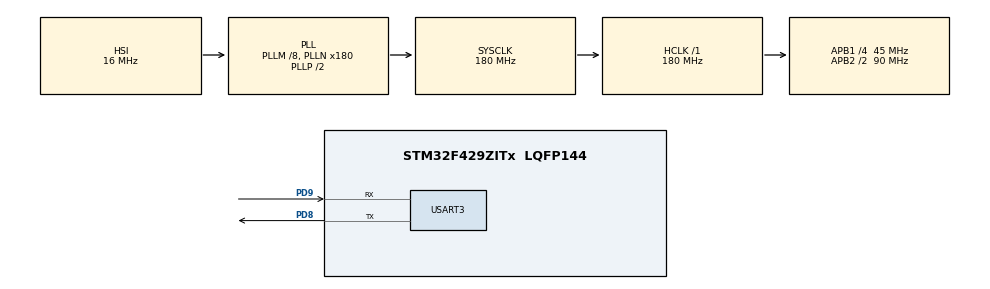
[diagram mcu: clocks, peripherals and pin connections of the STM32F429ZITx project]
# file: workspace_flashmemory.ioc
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Mcu.Family=STM32F4
Mcu.Name=STM32F429ZITx
Mcu.Package=LQFP144
NVIC.PriorityGroup=NVIC_PRIORITYGROUP_4
PA13.Mode=Serial_Wire
PA13.Signal=SYS_JTMS-SWDIO
PA14.Mode=Serial_Wire
PA14.Signal=SYS_JTCK-SWCLK
PC14/OSC32_IN.Mode=LSE-External-Oscillator
PC14/OSC32_IN.Signal=RCC_OSC32_IN
PC15/OSC32_OUT.Mode=LSE-External-Oscillator
PC15/OSC32_OUT.Signal=RCC_OSC32_OUT
PD8.Mode=Asynchronous
PD8.Signal=USART3_TX
PD9.Mode=Asynchronous
PD9.Signal=USART3_RX
ProjectManager.HeapSize=0x200
ProjectManager.StackSize=0x400
ProjectManager.TargetToolchain=STM32CubeIDE
RCC.48MHZClocksFreq_Value=90000000
RCC.AHBFreq_Value=180000000
RCC.APB1CLKDivider=RCC_HCLK_DIV4
RCC.APB1Freq_Value=45000000
RCC.APB1TimFreq_Value=90000000
RCC.APB2CLKDivider=RCC_HCLK_DIV2
RCC.APB2Freq_Value=90000000
RCC.APB2TimFreq_Value=180000000
RCC.CortexFreq_Value=180000000
RCC.HCLKFreq_Value=180000000
RCC.HSE_VALUE=25000000
RCC.HSI_VALUE=16000000
RCC.PLLM=8
RCC.PLLN=180
RCC.RCC_RTC_Clock_Source=RCC_RTCCLKSOURCE_LSE
RCC.SYSCLKFreq_VALUE=180000000
RCC.SYSCLKSource=RCC_SYSCLKSOURCE_PLLCLK
RCC.VCOOutputFreq_Value=360000000
USART3.VirtualMode=VM_ASYNC
VP_RTC_VS_RTC_Activate.Mode=RTC_Enabled
board=custom

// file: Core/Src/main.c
/* USER CODE BEGIN Header */
/**
  ******************************************************************************
  * @file           : main.c
  * @brief          : Main program body
  ******************************************************************************
  * @attention
  *
  * Copyright (c) 2022 STMicroelectronics.
  * All rights reserved.
  *
  * This software is licensed under terms that can be found in the LICENSE file
  * in the root directory of this software component.
  * If no LICENSE file comes with this software, it is provided AS-IS.
  *
  ******************************************************************************
  */
/* USER CODE END Header */
#include "main.h"
#include "rtc.h"
#include "usart.h"
#include "gpio.h"

/* USER CODE BEGIN PTD */
typedef struct FLAHTIME{
	uint8_t year;
	uint8_t month;
	uint8_t day;
	uint8_t format;
	uint8_t hour;
	uint8_t minutes;
	uint8_t seconds;
	uint8_t alramFormat;
	uint8_t alramHour;
	uint8_t alramMinutes;
	uint8_t alramSeconds;

} FT;
/* USER CODE END PTD */

/* USER CODE BEGIN PD */
#define FLASH_USER_START_ADDR   ADDR_FLASH_SECTOR_12   /* Start @ of user Flash area */
#define FLASH_USER_END_ADDR     ADDR_FLASH_SECTOR_23  +  GetSectorSize(ADDR_FLASH_SECTOR_23) - 1 /* End @ of user Flash area : sector start address + sector size -1 */

#define DATA_32                 ((uint32_t)0x12300078)

/* USER CODE END PD */

void SystemClock_Config(void);

/* USER CODE BEGIN 0 */
static FLASH_EraseInitTypeDef EraseInitStruct;
static uint32_t GetSector(uint32_t Address);
uint32_t FirstSector = 0, NbOfSectors = 0;
uint32_t Address = 0, SECTORError = 0;
__IO uint32_t data32 = 0 , MemoryProgramStatus = 0;
static uint32_t GetSectorSize(uint32_t Sector);
FT flashTime;
/* USER CODE END 0 */

int main(void)
{

  /* MCU Configuration--------------------------------------------------------*/

  /* Reset of all peripherals, Initializes the Flash interface and the Systick. */
  HAL_Init();

  /* Configure the system clock */
  SystemClock_Config();

  /* Initialize all configured peripherals */
  MX_GPIO_Init();
  MX_RTC_Init();
  MX_USART3_UART_Init();
  /* USER CODE BEGIN 2 */
  flashTime.format = 0; // AM
  flashTime.hour = 12;
  flashTime.minutes = 0;
  flashTime.seconds = 0;
  flashTime.alramFormat = 0; // AM
  flashTime.alramHour = 12;
  flashTime.alramMinutes = 0;
  flashTime.alramSeconds = 0;

  /* Unlock the Flash to enable the flash control register access *************/
  HAL_FLASH_Unlock();

  /* Erase the user Flash area
    (area defined by FLASH_USER_START_ADDR and FLASH_USER_END_ADDR) ***********/

  /* Get the 1st sector to erase */
  FirstSector = GetSector(FLASH_USER_START_ADDR); // 특정 섹터의 범위를 지정한다.
  /* Get the number of sector to erase from 1st sector*/
  NbOfSectors = GetSector(FLASH_USER_END_ADDR) - FirstSector + 1;
  /* Fill EraseInit structure*/
  EraseInitStruct.TypeErase     = FLASH_TYPEERASE_SECTORS; // 섹터단위로 지운다.
  EraseInitStruct.VoltageRange  = FLASH_VOLTAGE_RANGE_3; // 2.7~ 3.6V 사이의 전압을 사용한다.
  EraseInitStruct.Sector        = FirstSector;  // 지울 섹터의 범위
  EraseInitStruct.NbSectors     = NbOfSectors;

  /* Note: If an erase operation in Flash memory also concerns data in the data or instruction cache,
     you have to make sure that these data are rewritten before they are accessed during code
     execution. If this cannot be done safely, it is recommended to flush the caches by setting the
     DCRST and ICRST bits in the FLASH_CR register. */
  if(HAL_FLASHEx_Erase(&EraseInitStruct, &SECTORError) != HAL_OK)
  {
    /*
      Error occurred while sector erase.
      User can add here some code to deal with this error.
      SECTORError will contain the faulty sector and then to know the code error on this sector,
      user can call function 'HAL_FLASH_GetError()'
    */
    /* Infinite loop */

  }

  /* Program the user Flash area word by word
    (area defined by FLASH_USER_START_ADDR and FLASH_USER_END_ADDR) ***********/

  Address = FLASH_USER_START_ADDR;

/*  while(Address < FLASH_USER_END_ADDR)
  {
    if(HAL_FLASH_Program(FLASH_TYPEPROGRAM_WORD, Address, DATA_32) == HAL_OK)
    {
      Address = Address + 4;
    }
   else
    {
       Error occurred while writing data in Flash memory.
         User can add here some code to deal with this error

    }
  }*/

     if(HAL_FLASH_Program(FLASH_TYPEPROGRAM_WORD, Address, flashTime.format) == HAL_OK)
     {
       Address = Address + 4;
     }
    else
     {
       /* Error occurred while writing data in Flash memory.
          User can add here some code to deal with this error */

     }
     if(HAL_FLASH_Program(FLASH_TYPEPROGRAM_WORD, Address, flashTime.alramHour) == HAL_OK)
     {
       Address = Address + 4;
     }
    else
     {
       /* Error occurred while writing data in Flash memory.
          User can add here some code to deal with this error */

   }
     uint8_t velue1;
     velue1 =  *((uint32_t *)0x08100000);
     uint8_t velue2;
     velue2 = *((uint32_t *)0x08100004);

  /* Lock the Flash to disable the flash control register access (recommended
     to protect the FLASH memory against possible unwanted operation) *********/
  HAL_FLASH_Lock();

  /* USER CODE END 2 */

  /* Infinite loop */
  while (1)
  {

  }
}

void SystemClock_Config(void)
{
  RCC_OscInitTypeDef RCC_OscInitStruct = {0};
  RCC_ClkInitTypeDef RCC_ClkInitStruct = {0};

  /** Configure the main internal regulator output voltage
  */
  __HAL_RCC_PWR_CLK_ENABLE();
  __HAL_PWR_VOLTAGESCALING_CONFIG(PWR_REGULATOR_VOLTAGE_SCALE1);

  /** Initializes the RCC Oscillators according to the specified parameters
  * in the RCC_OscInitTypeDef structure.
  */
  RCC_OscInitStruct.OscillatorType = RCC_OSCILLATORTYPE_HSI|RCC_OSCILLATORTYPE_LSE;
  RCC_OscInitStruct.LSEState = RCC_LSE_ON;
  RCC_OscInitStruct.HSIState = RCC_HSI_ON;
  RCC_OscInitStruct.HSICalibrationValue = RCC_HSICALIBRATION_DEFAULT;
  RCC_OscInitStruct.PLL.PLLState = RCC_PLL_ON;
  RCC_OscInitStruct.PLL.PLLSource = RCC_PLLSOURCE_HSI;
  RCC_OscInitStruct.PLL.PLLM = 8;
  RCC_OscInitStruct.PLL.PLLN = 180;
  RCC_OscInitStruct.PLL.PLLP = RCC_PLLP_DIV2;
  RCC_OscInitStruct.PLL.PLLQ = 4;
  if (HAL_RCC_OscConfig(&RCC_OscInitStruct) != HAL_OK)
  {
    Error_Handler();
  }

  /** Activate the Over-Drive mode
  */
  if (HAL_PWREx_EnableOverDrive() != HAL_OK)
  {
    Error_Handler();
  }

  /** Initializes the CPU, AHB and APB buses clocks
  */
  RCC_ClkInitStruct.ClockType = RCC_CLOCKTYPE_HCLK|RCC_CLOCKTYPE_SYSCLK
                              |RCC_CLOCKTYPE_PCLK1|RCC_CLOCKTYPE_PCLK2;
  RCC_ClkInitStruct.SYSCLKSource = RCC_SYSCLKSOURCE_PLLCLK;
  RCC_ClkInitStruct.AHBCLKDivider = RCC_SYSCLK_DIV1;
  RCC_ClkInitStruct.APB1CLKDivider = RCC_HCLK_DIV4;
  RCC_ClkInitStruct.APB2CLKDivider = RCC_HCLK_DIV2;

  if (HAL_RCC_ClockConfig(&RCC_ClkInitStruct, FLASH_LATENCY_5) != HAL_OK)
  {
    Error_Handler();
  }
}

/* USER CODE BEGIN 4 */
static uint32_t GetSector(uint32_t Address)
{
  uint32_t sector = 0;

  if((Address < ADDR_FLASH_SECTOR_1) && (Address >= ADDR_FLASH_SECTOR_0))
  {
    sector = FLASH_SECTOR_0;
  }
  else if((Address < ADDR_FLASH_SECTOR_2) && (Address >= ADDR_FLASH_SECTOR_1))
  {
    sector = FLASH_SECTOR_1;
  }
  else if((Address < ADDR_FLASH_SECTOR_3) && (Address >= ADDR_FLASH_SECTOR_2))
  {
    sector = FLASH_SECTOR_2;
  }
  else if((Address < ADDR_FLASH_SECTOR_4) && (Address >= ADDR_FLASH_SECTOR_3))
  {
    sector = FLASH_SECTOR_3;
  }
  else if((Address < ADDR_FLASH_SECTOR_5) && (Address >= ADDR_FLASH_SECTOR_4))
  {
    sector = FLASH_SECTOR_4;
  }
  else if((Address < ADDR_FLASH_SECTOR_6) && (Address >= ADDR_FLASH_SECTOR_5))
  {
    sector = FLASH_SECTOR_5;
  }
  else if((Address < ADDR_FLASH_SECTOR_7) && (Address >= ADDR_FLASH_SECTOR_6))
  {
    sector = FLASH_SECTOR_6;
  }
  else if((Address < ADDR_FLASH_SECTOR_8) && (Address >= ADDR_FLASH_SECTOR_7))
  {
    sector = FLASH_SECTOR_7;
  }
  else if((Address < ADDR_FLASH_SECTOR_9) && (Address >= ADDR_FLASH_SECTOR_8))
  {
    sector = FLASH_SECTOR_8;
  }
  else if((Address < ADDR_FLASH_SECTOR_10) && (Address >= ADDR_FLASH_SECTOR_9))
  {
    sector = FLASH_SECTOR_9;
  }
  else if((Address < ADDR_FLASH_SECTOR_11) && (Address >= ADDR_FLASH_SECTOR_10))
  {
    sector = FLASH_SECTOR_10;
  }
  else if((Address < ADDR_FLASH_SECTOR_12) && (Address >= ADDR_FLASH_SECTOR_11))
  {
    sector = FLASH_SECTOR_11;
  }
  else if((Address < ADDR_FLASH_SECTOR_13) && (Address >= ADDR_FLASH_SECTOR_12))
  {
    sector = FLASH_SECTOR_12;
  }
  else if((Address < ADDR_FLASH_SECTOR_14) && (Address >= ADDR_FLASH_SECTOR_13))
  {
    sector = FLASH_SECTOR_13;
  }
  else if((Address < ADDR_FLASH_SECTOR_15) && (Address >= ADDR_FLASH_SECTOR_14))
  {
    sector = FLASH_SECTOR_14;
  }
  else if((Address < ADDR_FLASH_SECTOR_16) && (Address >= ADDR_FLASH_SECTOR_15))
  {
    sector = FLASH_SECTOR_15;
  }
  else if((Address < ADDR_FLASH_SECTOR_17) && (Address >= ADDR_FLASH_SECTOR_16))
  {
    sector = FLASH_SECTOR_16;
  }
  else if((Address < ADDR_FLASH_SECTOR_18) && (Address >= ADDR_FLASH_SECTOR_17))
  {
    sector = FLASH_SECTOR_17;
  }
  else if((Address < ADDR_FLASH_SECTOR_19) && (Address >= ADDR_FLASH_SECTOR_18))
  {
    sector = FLASH_SECTOR_18;
  }
  else if((Address < ADDR_FLASH_SECTOR_20) && (Address >= ADDR_FLASH_SECTOR_19))
  {
    sector = FLASH_SECTOR_19;
  }
  else if((Address < ADDR_FLASH_SECTOR_21) && (Address >= ADDR_FLASH_SECTOR_20))
  {
    sector = FLASH_SECTOR_20;
  }
  else if((Address < ADDR_FLASH_SECTOR_22) && (Address >= ADDR_FLASH_SECTOR_21))
  {
    sector = FLASH_SECTOR_21;
  }
  else if((Address < ADDR_FLASH_SECTOR_23) && (Address >= ADDR_FLASH_SECTOR_22))
  {
    sector = FLASH_SECTOR_22;
  }
  else /* (Address < FLASH_END_ADDR) && (Address >= ADDR_FLASH_SECTOR_23) */
  {
    sector = FLASH_SECTOR_23;
  }
  return sector;
}

static uint32_t GetSectorSize(uint32_t Sector)
{
  uint32_t sectorsize = 0x00;
  if((Sector == FLASH_SECTOR_0) || (Sector == FLASH_SECTOR_1) || (Sector == FLASH_SECTOR_2) ||\
     (Sector == FLASH_SECTOR_3) || (Sector == FLASH_SECTOR_12) || (Sector == FLASH_SECTOR_13) ||\
     (Sector == FLASH_SECTOR_14) || (Sector == FLASH_SECTOR_15))
  {
    sectorsize = 16 * 1024;
  }
  else if((Sector == FLASH_SECTOR_4) || (Sector == FLASH_SECTOR_16))
  {
    sectorsize = 64 * 1024;
  }
  else
  {
    sectorsize = 128 * 1024;
  }
  return sectorsize;
}
/* USER CODE END 4 */

void Error_Handler(void)
{
  __disable_irq();
  while (1)
  {
  }
}
